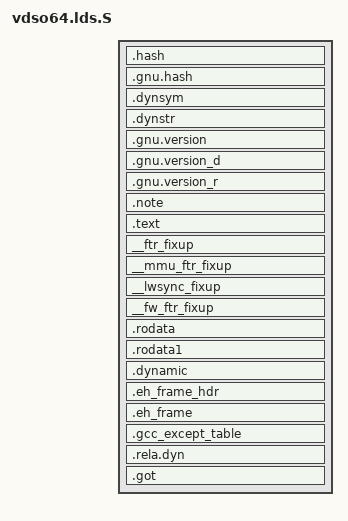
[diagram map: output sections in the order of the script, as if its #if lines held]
FASTVC-BENCH-CORPUS:linux-main-100k-v1-e0bd41dc-8e12-4f1b-978d-a3645ae59da0
/* SPDX-License-Identifier: GPL-2.0 */
/*
 * This is the infamous ld script for the 64 bits vdso
 * library
 */
#include <asm/vdso.h>
#include <asm/page.h>
#include <asm-generic/vmlinux.lds.h>

#ifdef __LITTLE_ENDIAN__
OUTPUT_FORMAT("elf64-powerpcle", "elf64-powerpcle", "elf64-powerpcle")
#else
OUTPUT_FORMAT("elf64-powerpc", "elf64-powerpc", "elf64-powerpc")
#endif
OUTPUT_ARCH(powerpc:common64)
ENTRY(_start)

SECTIONS
{
	PROVIDE(_vdso_datapage = . - PAGE_SIZE);
	. = SIZEOF_HEADERS;

	.hash		: { *(.hash) }			:text
	.gnu.hash	: { *(.gnu.hash) }
	.dynsym		: { *(.dynsym) }
	.dynstr		: { *(.dynstr) }
	.gnu.version	: { *(.gnu.version) }
	.gnu.version_d	: { *(.gnu.version_d) }
	.gnu.version_r	: { *(.gnu.version_r) }

	.note		: { *(.note.*) }		:text	:note

	. = ALIGN(16);
	.text		: {
		*(.text .stub .text.* .gnu.linkonce.t.* __ftr_alt_*)
		*(.sfpr .glink)
	}						:text
	PROVIDE(__etext = .);
	PROVIDE(_etext = .);
	PROVIDE(etext = .);

	. = ALIGN(8);
	VDSO_ftr_fixup_start = .;
	__ftr_fixup	: { *(__ftr_fixup) }
	VDSO_ftr_fixup_end = .;

	. = ALIGN(8);
	VDSO_mmu_ftr_fixup_start = .;
	__mmu_ftr_fixup	: { *(__mmu_ftr_fixup) }
	VDSO_mmu_ftr_fixup_end = .;

	. = ALIGN(8);
	VDSO_lwsync_fixup_start = .;
	__lwsync_fixup	: { *(__lwsync_fixup) }
	VDSO_lwsync_fixup_end = .;

	. = ALIGN(8);
	VDSO_fw_ftr_fixup_start = .;
	__fw_ftr_fixup	: { *(__fw_ftr_fixup) }
	VDSO_fw_ftr_fixup_end = .;

	/*
	 * Other stuff is appended to the text segment:
	 */
	.rodata		: { *(.rodata .rodata.* .gnu.linkonce.r.*) }
	.rodata1	: { *(.rodata1) }

	.dynamic	: { *(.dynamic) }		:text	:dynamic

	.eh_frame_hdr	: { *(.eh_frame_hdr) }		:text	:eh_frame_hdr
	.eh_frame	: { KEEP (*(.eh_frame)) }	:text
	.gcc_except_table : { *(.gcc_except_table) }
	.rela.dyn ALIGN(8) : { *(.rela.dyn) }

	.got ALIGN(8)	: { *(.got .toc) }
/* bench 19726.1.0 10fd95300af7 */
/* bench 19726.1.1 93e3b017017c */
/* bench 19726.1.2 e2715e9adb3b */
/* bench 19726.1.3 c653f70662af */
/* bench 19726.1.4 ec6e0b30c16f */
/* bench 19726.1.5 17c06764fd61 */
/* bench 19726.1.6 7017d117c025 */
/* bench 19726.1.7 be033a207272 */
/* bench 19726.1.8 7d3c9ba09a16 */
/* bench 19726.1.9 aae6470e95e3 */
/* bench 19726.1.10 8823f6cec758 */
/* bench 19726.1.11 7d4c3bdc1e0f */

	STABS_DEBUG
	DWARF_DEBUG
	ELF_DETAILS

	/DISCARD/	: {
		*(.note.GNU-stack)
		*(.branch_lt)
		*(.data .data.* .gnu.linkonce.d.* .sdata*)
		*(.bss .sbss .dynbss .dynsbss)
		*(.opd)
	}
}

/*
 * Very old versions of ld do not recognize this name token; use the constant.
 */
#define PT_GNU_EH_FRAME	0x6474e550

/*
 * We must supply the ELF program headers explicitly to get just one
 * PT_LOAD segment, and set the flags explicitly to make segments read-only.
 */
PHDRS
{
	text		PT_LOAD FILEHDR PHDRS FLAGS(5);	/* PF_R|PF_X */
	dynamic		PT_DYNAMIC FLAGS(4);		/* PF_R */
	note		PT_NOTE FLAGS(4);		/* PF_R */
	eh_frame_hdr	PT_GNU_EH_FRAME;
}

/*
 * This controls what symbols we export from the DSO.
 */
VERSION
/* bench 20200.2.0 a60f8e210390 */
/* bench 20200.2.1 1d33699a9547 */
/* bench 20200.2.2 933dcdbdbe75 */
/* bench 20200.2.3 1380c4502503 */
/* bench 20200.2.4 a3f396114d2c */
/* bench 20200.2.5 f3769746a5a3 */
/* bench 20200.2.6 dba34353c499 */
/* bench 20200.2.7 e85bbc392ca2 */
/* bench 20200.2.8 3b8f250dbb72 */
/* bench 20200.2.9 e24ceda695d1 */
/* bench 20200.2.10 6e522844809d */
{
	VDSO_VERSION_STRING {
	global:
		__kernel_get_syscall_map;
		__kernel_gettimeofday;
		__kernel_clock_gettime;
		__kernel_clock_getres;
		__kernel_get_tbfreq;
		__kernel_sync_dicache;
		__kernel_sigtramp_rt64;
		__kernel_getcpu;
		__kernel_time;

	local: *;
	};
}

/*
 * Make the sigreturn code visible to the kernel.
 */
VDSO_sigtramp_rt64	= __kernel_start_sigtramp_rt64;
